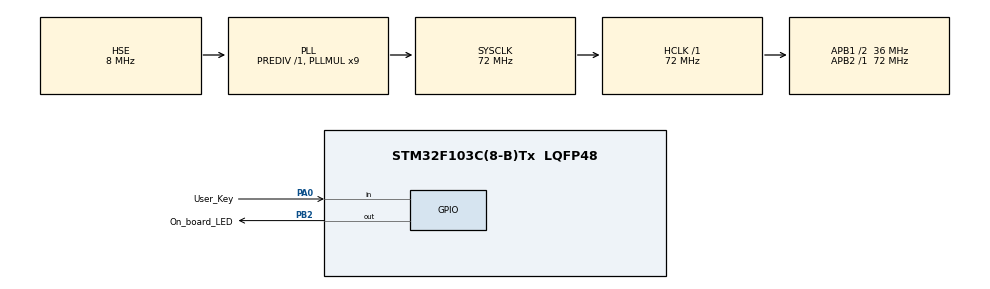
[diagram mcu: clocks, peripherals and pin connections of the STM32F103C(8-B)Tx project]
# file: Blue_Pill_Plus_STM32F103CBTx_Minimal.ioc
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Mcu.Family=STM32F1
Mcu.Name=STM32F103C(8-B)Tx
Mcu.Package=LQFP48
NVIC.PriorityGroup=NVIC_PRIORITYGROUP_4
PA0-WKUP.GPIO_Label=User_Key
PA0-WKUP.Signal=GPIO_Input
PA13.Mode=Serial_Wire
PA13.Signal=SYS_JTMS-SWDIO
PA14.Mode=Serial_Wire
PA14.Signal=SYS_JTCK-SWCLK
PB2.GPIO_Label=On_board_LED
PB2.Signal=GPIO_Output
PC14-OSC32_IN.Mode=LSE-External-Oscillator
PC14-OSC32_IN.Signal=RCC_OSC32_IN
PC15-OSC32_OUT.Mode=LSE-External-Oscillator
PC15-OSC32_OUT.Signal=RCC_OSC32_OUT
PD0-OSC_IN.Mode=HSE-External-Oscillator
PD0-OSC_IN.Signal=RCC_OSC_IN
PD1-OSC_OUT.Mode=HSE-External-Oscillator
PD1-OSC_OUT.Signal=RCC_OSC_OUT
ProjectManager.HeapSize=0x200
ProjectManager.StackSize=0x400
ProjectManager.TargetToolchain=Makefile
RCC.AHBFreq_Value=72000000
RCC.APB1CLKDivider=RCC_HCLK_DIV2
RCC.APB1Freq_Value=36000000
RCC.APB1TimFreq_Value=72000000
RCC.APB2Freq_Value=72000000
RCC.APB2TimFreq_Value=72000000
RCC.HCLKFreq_Value=72000000
RCC.PLLMUL=RCC_PLL_MUL9
RCC.PLLSourceVirtual=RCC_PLLSOURCE_HSE
RCC.RTCClockSelection=RCC_RTCCLKSOURCE_LSE
RCC.SYSCLKFreq_VALUE=72000000
RCC.SYSCLKSource=RCC_SYSCLKSOURCE_PLLCLK
RCC.USBFreq_Value=72000000
VP_RTC_VS_RTC_Activate.Mode=RTC_Enabled
VP_RTC_VS_RTC_Calendar.Mode=RTC_Calendar
board=custom

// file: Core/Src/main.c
/* USER CODE BEGIN Header */
/**
  ******************************************************************************
  * @file           : main.c
  * @brief          : Main program body
  ******************************************************************************
  * @attention
  *
  * Copyright (c) 2025 STMicroelectronics.
  * All rights reserved.
  *
  * This software is licensed under terms that can be found in the LICENSE file
  * in the root directory of this software component.
  * If no LICENSE file comes with this software, it is provided AS-IS.
  *
  ******************************************************************************
  */
/* USER CODE END Header */
#include "main.h"

RTC_HandleTypeDef hrtc;

void SystemClock_Config(void);
static void MX_GPIO_Init(void);
static void MX_RTC_Init(void);

int main(void)
{

  /* MCU Configuration--------------------------------------------------------*/

  /* Reset of all peripherals, Initializes the Flash interface and the Systick. */
  HAL_Init();

  /* Configure the system clock */
  SystemClock_Config();

  /* Initialize all configured peripherals */
  MX_GPIO_Init();
  MX_RTC_Init();

  /* Infinite loop */
  while (1)
  {

    /* USER CODE BEGIN 3 */
    /* Small delay for animation speed (~2 fps) */
    HAL_Delay(500);

    /* Toggle onboard LED */
    HAL_GPIO_TogglePin(On_board_LED_GPIO_Port, On_board_LED_Pin);
  }
  /* USER CODE END 3 */
}

void SystemClock_Config(void)
{
  RCC_OscInitTypeDef RCC_OscInitStruct = {0};
  RCC_ClkInitTypeDef RCC_ClkInitStruct = {0};
  RCC_PeriphCLKInitTypeDef PeriphClkInit = {0};

  /** Initializes the RCC Oscillators according to the specified parameters
  * in the RCC_OscInitTypeDef structure.
  */
  RCC_OscInitStruct.OscillatorType = RCC_OSCILLATORTYPE_HSE|RCC_OSCILLATORTYPE_LSE;
  RCC_OscInitStruct.HSEState = RCC_HSE_ON;
  RCC_OscInitStruct.HSEPredivValue = RCC_HSE_PREDIV_DIV1;
  RCC_OscInitStruct.LSEState = RCC_LSE_ON;
  RCC_OscInitStruct.HSIState = RCC_HSI_ON;
  RCC_OscInitStruct.PLL.PLLState = RCC_PLL_ON;
  RCC_OscInitStruct.PLL.PLLSource = RCC_PLLSOURCE_HSE;
  RCC_OscInitStruct.PLL.PLLMUL = RCC_PLL_MUL9;
  if (HAL_RCC_OscConfig(&RCC_OscInitStruct) != HAL_OK)
  {
    Error_Handler();
  }

  /** Initializes the CPU, AHB and APB buses clocks
  */
  RCC_ClkInitStruct.ClockType = RCC_CLOCKTYPE_HCLK|RCC_CLOCKTYPE_SYSCLK
                              |RCC_CLOCKTYPE_PCLK1|RCC_CLOCKTYPE_PCLK2;
  RCC_ClkInitStruct.SYSCLKSource = RCC_SYSCLKSOURCE_PLLCLK;
  RCC_ClkInitStruct.AHBCLKDivider = RCC_SYSCLK_DIV1;
  RCC_ClkInitStruct.APB1CLKDivider = RCC_HCLK_DIV2;
  RCC_ClkInitStruct.APB2CLKDivider = RCC_HCLK_DIV1;

  if (HAL_RCC_ClockConfig(&RCC_ClkInitStruct, FLASH_LATENCY_2) != HAL_OK)
  {
    Error_Handler();
  }
  PeriphClkInit.PeriphClockSelection = RCC_PERIPHCLK_RTC;
  PeriphClkInit.RTCClockSelection = RCC_RTCCLKSOURCE_LSE;
  if (HAL_RCCEx_PeriphCLKConfig(&PeriphClkInit) != HAL_OK)
  {
    Error_Handler();
  }
}

static void MX_RTC_Init(void)
{

  RTC_TimeTypeDef sTime = {0};
  RTC_DateTypeDef DateToUpdate = {0};

  /** Initialize RTC Only
  */
  hrtc.Instance = RTC;
  hrtc.Init.AsynchPrediv = RTC_AUTO_1_SECOND;
  hrtc.Init.OutPut = RTC_OUTPUTSOURCE_ALARM;
  if (HAL_RTC_Init(&hrtc) != HAL_OK)
  {
    Error_Handler();
  }

  /** Initialize RTC and set the Time and Date
  */
  sTime.Hours = 0x0;
  sTime.Minutes = 0x0;
  sTime.Seconds = 0x0;

  if (HAL_RTC_SetTime(&hrtc, &sTime, RTC_FORMAT_BCD) != HAL_OK)
  {
    Error_Handler();
  }
  DateToUpdate.WeekDay = RTC_WEEKDAY_MONDAY;
  DateToUpdate.Month = RTC_MONTH_JANUARY;
  DateToUpdate.Date = 0x1;
  DateToUpdate.Year = 0x0;

  if (HAL_RTC_SetDate(&hrtc, &DateToUpdate, RTC_FORMAT_BCD) != HAL_OK)
  {
    Error_Handler();
  }

}

static void MX_GPIO_Init(void)
{
  GPIO_InitTypeDef GPIO_InitStruct = {0};

  /* GPIO Ports Clock Enable */
  __HAL_RCC_GPIOC_CLK_ENABLE();
  __HAL_RCC_GPIOD_CLK_ENABLE();
  __HAL_RCC_GPIOA_CLK_ENABLE();
  __HAL_RCC_GPIOB_CLK_ENABLE();

  /*Configure GPIO pin Output Level */
  HAL_GPIO_WritePin(On_board_LED_GPIO_Port, On_board_LED_Pin, GPIO_PIN_RESET);

  /*Configure GPIO pin : User_Key_Pin */
  GPIO_InitStruct.Pin = User_Key_Pin;
  GPIO_InitStruct.Mode = GPIO_MODE_INPUT;
  GPIO_InitStruct.Pull = GPIO_NOPULL;
  HAL_GPIO_Init(User_Key_GPIO_Port, &GPIO_InitStruct);

  /*Configure GPIO pin : On_board_LED_Pin */
  GPIO_InitStruct.Pin = On_board_LED_Pin;
  GPIO_InitStruct.Mode = GPIO_MODE_OUTPUT_PP;
  GPIO_InitStruct.Pull = GPIO_NOPULL;
  GPIO_InitStruct.Speed = GPIO_SPEED_FREQ_LOW;
  HAL_GPIO_Init(On_board_LED_GPIO_Port, &GPIO_InitStruct);

}

void Error_Handler(void)
{
  __disable_irq();
  while (1)
  {
  }
}
